AUTOSAR XML (schema 00048)
package /ComponentTypes
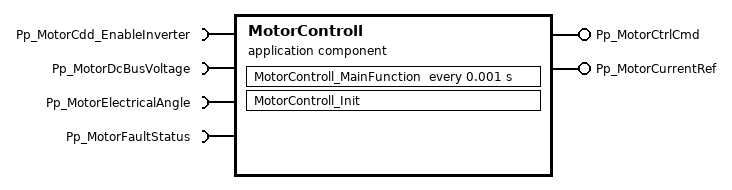
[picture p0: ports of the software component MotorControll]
  application sw component type MotorControll
    require port Pp_MotorCdd_EnableInverter: client-com-spec=EnableInverter, required-interface=Pp_MotorCdd_EnableInverter
    provide port Pp_MotorCtrlCmd: nonqueued-sender-com-spec{data-element=MotorMode, init-value=0}, provided-interface=Pp_MotorCtrlCmd
    provide port Pp_MotorCurrentRef: provided-com-specs=[{data-element=Iq_Ref, init-value=0}, {data-element=Id_Ref, init-value=0}], provided-interface=Pp_MotorCurrentRef
    require port Pp_MotorDcBusVoltage: nonqueued-receiver-com-spec{data-element=Vbus, filter=data-filter-type=ALWAYS, init-value=0}, required-interface=Pp_MotorDcBusVoltage
    require port Pp_MotorElectricalAngle: nonqueued-receiver-com-spec{data-element=ElectricAngle, filter=data-filter-type=ALWAYS, init-value=0}, required-interface=Pp_MotorElectricalAngle
    require port Pp_MotorFaultStatus: nonqueued-receiver-com-spec{data-element=tle9180_Ov_Fault, filter=data-filter-type=ALWAYS, init-value=0}, required-interface=Pp_MotorFaultStatus
    behavior MotorControll_InternalBehavior: data-type-mapping=MotorDataTypeMappingSet
      init event MotorControll_InitEvent: start-on-event=MotorControll_Init
      timing event TMT_MotorControll_MainFunction: start-on-event=MotorControll_MainFunction, period=0.001
      runnable MotorControll_Init
      runnable MotorControll_MainFunction
        data-receive-point-by-arguments:
          access REC_Pp_MotorDcBusVoltage_Vbus: accessed-variable=Pp_MotorDcBusVoltage.Vbus
          access REC_Pp_MotorElectricalAngle_ElectricAngle: accessed-variable=Pp_MotorElectricalAngle.ElectricAngle
          access REC_Pp_MotorFaultStatus_tle9180_Ov_Fault: accessed-variable=Pp_MotorFaultStatus.tle9180_Ov_Fault
        data-send-points:
          access SEND_Pp_MotorCtrlCmd_MotorMode: accessed-variable=Pp_MotorCtrlCmd.MotorMode
          access SEND_Pp_MotorCurrentRef_Id_Ref: accessed-variable=Pp_MotorCurrentRef.Id_Ref
          access SEND_Pp_MotorCurrentRef_Iq_Ref: accessed-variable=Pp_MotorCurrentRef.Iq_Ref
  swc implementation MotorControll_Implementation: behavior=MotorControll_InternalBehavior
